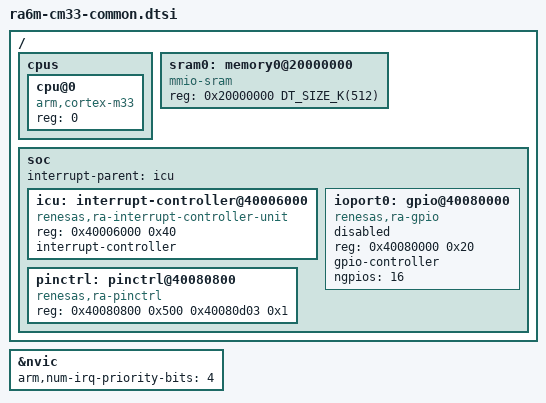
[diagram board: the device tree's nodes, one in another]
#include <mem.h>
#include <freq.h>
#include <arm/armv8-m.dtsi>
#include <zephyr/dt-bindings/interrupt-controller/renesas-ra-icu.h>

/ {
	cpus {
		#address-cells = <1>;
		#size-cells = <0>;

		cpu@0 {
			device_type = "cpu";
			compatible = "arm,cortex-m33";
			reg = <0>;
		};
	};

	sram0: memory0@20000000 {
		compatible = "mmio-sram";
                reg = <0x20000000 DT_SIZE_K(512)>;
        };

        soc {
		interrupt-parent = <&icu>;
		icu: interrupt-controller@40006000 {
			compatible = "renesas,ra-interrupt-controller-unit";
			reg = <0x40006000 0x40>;
			reg-names = "icu";
			interrupt-controller;
			#interrupt-cells = <3>;
		};

		ioport0: gpio@40080000 {
			compatible = "renesas,ra-gpio";
			reg = <0x40080000 0x20>;

			gpio-controller;
			#gpio-cells = <2>;
			ngpios = <16>;
                        status = "disabled";
                };

		pinctrl: pinctrl@40080800 {
			compatible = "renesas,ra-pinctrl";
			reg = <0x40080800 0x500 0x40080d03 0x1>;
			reg-names = "pfs", "pmisc_pwpr";
			status = "okay";
		};
        };
};

&nvic {
	arm,num-irq-priority-bits = <4>;
};
